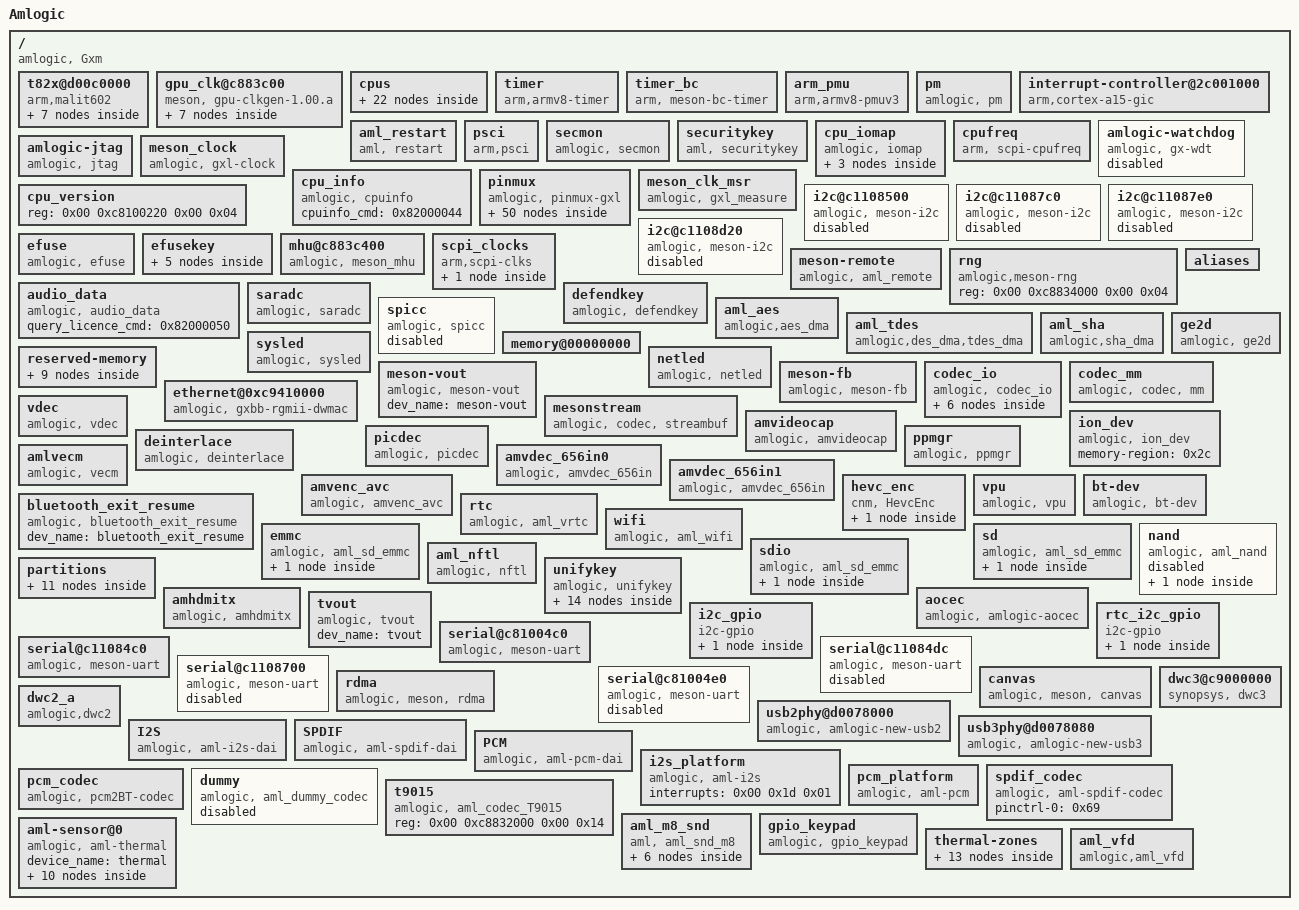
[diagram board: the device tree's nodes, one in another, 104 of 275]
/dts-v1/;

/ {
	model = "Amlogic";
	compatible = "amlogic, Gxm";
	amlogic-dt-id = "gxm_m12s_1g";
	interrupt-parent = <0x01>;
	#address-cells = <0x02>;
	#size-cells = <0x02>;

	t82x@d00c0000 {
		compatible = "arm,malit602", "arm,malit60x", "arm,malit6xx", "arm,mali-midgard";
		#cooling-cells = <0x02>;
		reg = <0x00 0xd00c0000 0x00 0x100000 0x00 0xc1104440 0x00 0x1000 0x00 0xc8100000 0x00 0x1000 0x00 0xc883c000 0x00 0x1000 0x00 0xc1104440 0x00 0x1000>;
		interrupt-parent = <0x01>;
		interrupts = <0x00 0xa0 0x04 0x00 0xa1 0x04 0x00 0xa2 0x04>;
		interrupt-names = "GPU", "MMU", "JOB";
		num_of_pp = <0x03>;
		sc_mpp = <0x01>;
		operating-points = <0xa2c2a 0xf4240 0x7a120 0xf4240 0x61a80 0xf4240 0x45c12 0xf4240 0x3d090 0xf4240 0x1e848 0xf4240>;
		tbl = <0x02 0x03 0x04 0x05 0x05>;
		clocks = <0x06 0x08 0x06 0x09 0x06 0x11 0x06 0x12 0x06 0x1e 0x06 0x15 0x06 0x13 0x06 0x14>;
		clock-names = "fclk_div3", "fclk_div4", "fclk_div5", "fclk_div7", "gp0_pll", "clk_gpu", "clk_gpu_0", "clk_gpu_1";
		linux,phandle = <0x7e>;
		phandle = <0x7e>;

		clk125_cfg {
			clk_freq = <0x7735940>;
			clk_parent = "fclk_div4";
			clkp_freq = <0x1dcd6500>;
			voltage = <0x47e>;
			keep_count = <0x05>;
			threshold = <0x1e 0x78>;
		};

		dvfs250_cfg {
			clk_freq = <0xee6b280>;
			clk_parent = "fclk_div4";
			clkp_freq = <0x1dcd6500>;
			voltage = <0x47e>;
			keep_count = <0x05>;
			threshold = <0x50 0xaa>;
		};

		dvfs285_cfg {
			clk_freq = <0x1107a650>;
			clk_parent = "fclk_div7";
			clkp_freq = <0x1107a650>;
			voltage = <0x47e>;
			keep_count = <0x05>;
			threshold = <0x64 0xbe>;
			linux,phandle = <0x02>;
			phandle = <0x02>;
		};

		dvfs400_cfg {
			clk_freq = <0x17d78400>;
			clk_parent = "fclk_div5";
			clkp_freq = <0x17d78400>;
			voltage = <0x47e>;
			keep_count = <0x05>;
			threshold = <0x98 0xcf>;
			linux,phandle = <0x03>;
			phandle = <0x03>;
		};

		dvfs500_cfg {
			clk_freq = <0x1dcd6500>;
			clk_parent = "fclk_div4";
			clkp_freq = <0x1dcd6500>;
			voltage = <0x47e>;
			keep_count = <0x05>;
			threshold = <0xb4 0xdc>;
			linux,phandle = <0x04>;
			phandle = <0x04>;
		};

		dvfs666_cfg {
			clk_freq = <0x27b25a80>;
			clk_parent = "fclk_div3";
			clkp_freq = <0x27b25a80>;
			voltage = <0x47e>;
			keep_count = <0x05>;
			threshold = <0xd2 0xec>;
			linux,phandle = <0x05>;
			phandle = <0x05>;
		};

		dvfs800_cfg {
			clk_freq = <0x2f34f600>;
			clk_parent = "gp0_pll";
			clkp_freq = <0x2f34f600>;
			voltage = <0x47e>;
			keep_count = <0x05>;
			threshold = <0xe6 0xff>;
		};
	};

	gpu_clk@c883c00 {
		compatible = "meson, gpu-clkgen-1.00.a";
		#clock-cells = <0x00>;
		reg = <0x00 0xc883c000 0x00 0x1000>;
		clocks = <0x06 0x08 0x06 0x09 0x06 0x11 0x06 0x12 0x06 0x1e 0x06 0x15 0x06 0x13 0x06 0x14>;
		clock-names = "fclk_div3", "fclk_div4", "fclk_div5", "fclk_div7", "gp0_pll", "clk_gpu", "clk_gpu_0", "clk_gpu_1";
		clock-output-names = "clk_mali";
		tbl = <0x07 0x08 0x09 0x0a 0x0b 0x0c>;

		clk125_cfg {
			clk_freq = <0x7735940>;
			clk_parent = "fclk_div4";
			clkp_freq = <0x1dcd6500>;
			voltage = <0x47e>;
			keep_count = <0x05>;
			threshold = <0x1e 0x78>;
			linux,phandle = <0x07>;
			phandle = <0x07>;
		};

		clk250_cfg {
			clk_freq = <0xee6b280>;
			clk_parent = "fclk_div4";
			clkp_freq = <0x1dcd6500>;
			voltage = <0x47e>;
			keep_count = <0x05>;
			threshold = <0x50 0xaa>;
			linux,phandle = <0x08>;
			phandle = <0x08>;
		};

		clk285_cfg {
			clk_freq = <0x1107a650>;
			clk_parent = "fclk_div7";
			clkp_freq = <0x1107a650>;
			voltage = <0x47e>;
			keep_count = <0x05>;
			threshold = <0x64 0xbe>;
			linux,phandle = <0x09>;
			phandle = <0x09>;
		};

		clk400_cfg {
			clk_freq = <0x17d78400>;
			clk_parent = "fclk_div5";
			clkp_freq = <0x17d78400>;
			voltage = <0x47e>;
			keep_count = <0x05>;
			threshold = <0x98 0xcf>;
			linux,phandle = <0x0a>;
			phandle = <0x0a>;
		};

		clk500_cfg {
			clk_freq = <0x1dcd6500>;
			clk_parent = "fclk_div4";
			clkp_freq = <0x1dcd6500>;
			voltage = <0x47e>;
			keep_count = <0x05>;
			threshold = <0xb4 0xdc>;
			linux,phandle = <0x0b>;
			phandle = <0x0b>;
		};

		clk666_cfg {
			clk_freq = <0x27bc8410>;
			clk_parent = "fclk_div3";
			clkp_freq = <0x27bc8410>;
			voltage = <0x47e>;
			keep_count = <0x05>;
			threshold = <0xd2 0xec>;
			linux,phandle = <0x0c>;
			phandle = <0x0c>;
		};

		clk720_cfg {
			clk_freq = <0x2aea5400>;
			clk_parent = "gp0_pll";
			clkp_freq = <0x2aea5400>;
			voltage = <0x47e>;
			keep_count = <0x05>;
			threshold = <0xe6 0xff>;
		};
	};

	cpus {
		#address-cells = <0x02>;
		#size-cells = <0x00>;

		cpu-map {

			cluster0 {
				#cooling-cells = <0x02>;
				linux,phandle = <0x7a>;
				phandle = <0x7a>;

				core0 {
					cpu = <0x0d>;
				};

				core1 {
					cpu = <0x0e>;
				};

				core2 {
					cpu = <0x0f>;
				};

				core3 {
					cpu = <0x10>;
				};
			};

			cluster1 {
				#cooling-cells = <0x02>;
				linux,phandle = <0x7b>;
				phandle = <0x7b>;

				core0 {
					cpu = <0x11>;
				};

				core1 {
					cpu = <0x12>;
				};

				core2 {
					cpu = <0x13>;
				};

				core3 {
					cpu = <0x14>;
				};
			};
		};

		cpu@0 {
			device_type = "cpu";
			compatible = "arm,cortex-a53", "arm,armv8";
			reg = <0x00 0x00>;
			enable-method = "psci";
			clocks = <0x15 0x00>;
			clock-names = "cpu-cluster.0";
			cpu-idle-states = <0x16 0x17>;
			linux,phandle = <0x0d>;
			phandle = <0x0d>;
		};

		cpu@1 {
			device_type = "cpu";
			compatible = "arm,cortex-a53", "arm,armv8";
			reg = <0x00 0x01>;
			enable-method = "psci";
			clocks = <0x15 0x00>;
			clock-names = "cpu-cluster.0";
			cpu-idle-states = <0x16 0x17>;
			linux,phandle = <0x0e>;
			phandle = <0x0e>;
		};

		cpu@2 {
			device_type = "cpu";
			compatible = "arm,cortex-a53", "arm,armv8";
			reg = <0x00 0x02>;
			enable-method = "psci";
			clocks = <0x15 0x00>;
			clock-names = "cpu-cluster.0";
			cpu-idle-states = <0x16 0x17>;
			linux,phandle = <0x0f>;
			phandle = <0x0f>;
		};

		cpu@3 {
			device_type = "cpu";
			compatible = "arm,cortex-a53", "arm,armv8";
			reg = <0x00 0x03>;
			enable-method = "psci";
			clocks = <0x15 0x00>;
			clock-names = "cpu-cluster.0";
			cpu-idle-states = <0x16 0x17>;
			linux,phandle = <0x10>;
			phandle = <0x10>;
		};

		cpu@100 {
			device_type = "cpu";
			compatible = "arm,cortex-a53", "arm,armv8";
			reg = <0x00 0x100>;
			enable-method = "psci";
			clocks = <0x15 0x01>;
			clock-names = "cpu-cluster.1";
			cpu-idle-states = <0x16 0x17>;
			linux,phandle = <0x11>;
			phandle = <0x11>;
		};

		cpu@101 {
			device_type = "cpu";
			compatible = "arm,cortex-a53", "arm,armv8";
			reg = <0x00 0x101>;
			enable-method = "psci";
			clocks = <0x15 0x01>;
			clock-names = "cpu-cluster.1";
			cpu-idle-states = <0x16 0x17>;
			linux,phandle = <0x12>;
			phandle = <0x12>;
		};

		cpu@102 {
			device_type = "cpu";
			compatible = "arm,cortex-a53", "arm,armv8";
			reg = <0x00 0x102>;
			enable-method = "psci";
			clocks = <0x15 0x01>;
			clock-names = "cpu-cluster.1";
			cpu-idle-states = <0x16 0x17>;
			linux,phandle = <0x13>;
			phandle = <0x13>;
		};

		cpu@103 {
			device_type = "cpu";
			compatible = "arm,cortex-a53", "arm,armv8";
			reg = <0x00 0x103>;
			enable-method = "psci";
			clocks = <0x15 0x01>;
			clock-names = "cpu-cluster.1";
			cpu-idle-states = <0x16 0x17>;
			linux,phandle = <0x14>;
			phandle = <0x14>;
		};

		idle-states {
			entry-method = "arm,psci";

			cpu-sleep-0 {
				compatible = "arm, idle-state";
				arm,psci-suspend-param = <0x10000>;
				local-timer-stop;
				entry-latency-us = <0x1388>;
				exit-latency-us = <0x1f40>;
				min-residency-us = <0x4e20>;
				linux,phandle = <0x16>;
				phandle = <0x16>;
			};

			cluster-sleep-0 {
				compatible = "arm, idle-state";
				arm,psci-suspend-param = <0x1010000>;
				local-timer-stop;
				entry-latency-us = <0x1388>;
				exit-latency-us = <0x1f40>;
				min-residency-us = <0x61a8>;
				linux,phandle = <0x17>;
				phandle = <0x17>;
			};
		};
	};

	timer {
		compatible = "arm,armv8-timer";
		interrupts = <0x01 0x0d 0xff01 0x01 0x0e 0xff01 0x01 0x0b 0xff01 0x01 0x0a 0xff01>;
	};

	timer_bc {
		compatible = "arm, meson-bc-timer";
		reg = <0x00 0xc1109990 0x00 0x04 0x00 0xc1109994 0x00 0x04>;
		timer_name = "Meson TimerF";
		clockevent-rating = <0x12c>;
		clockevent-shift = <0x14>;
		clockevent-features = <0x23>;
		interrupts = <0x00 0x3c 0x01>;
		bit_enable = <0x10>;
		bit_mode = <0x0c>;
		bit_resolution = <0x00>;
	};

	arm_pmu {
		compatible = "arm,armv8-pmuv3";
		interrupts = <0x00 0x89 0x04 0x00 0x8a 0x04 0x00 0x99 0x04 0x00 0x9a 0x04>;
	};

	pm {
		compatible = "amlogic, pm";
		device_name = "aml_pm";
		gxbaby-suspend;
		reg = <0x00 0xc81000a8 0x00 0x04 0x00 0xc810023c 0x00 0x04>;
	};

	interrupt-controller@2c001000 {
		compatible = "arm,cortex-a15-gic", "arm,cortex-a9-gic";
		#interrupt-cells = <0x03>;
		#address-cells = <0x00>;
		interrupt-controller;
		reg = <0x00 0xc4301000 0x00 0x1000 0x00 0xc4302000 0x00 0x100>;
		interrupts = <0x01 0x09 0xf04>;
		linux,phandle = <0x01>;
		phandle = <0x01>;
	};

	aml_restart {
		compatible = "aml, restart";
		sys_reset = <0x84000009>;
		sys_poweroff = <0x84000008>;
	};

	psci {
		compatible = "arm,psci";
		method = "smc";
		cpu_suspend = <0xc4000001>;
		cpu_off = <0x84000002>;
		cpu_on = <0xc4000003>;
		migrate = <0xc4000005>;
	};

	secmon {
		compatible = "amlogic, secmon";
		memory-region = <0x18>;
		in_base_func = <0x82000020>;
		out_base_func = <0x82000021>;
	};

	securitykey {
		compatible = "aml, securitykey";
		storage_query = <0x82000060>;
		storage_read = <0x82000061>;
		storage_write = <0x82000062>;
		storage_tell = <0x82000063>;
		storage_verify = <0x82000064>;
		storage_status = <0x82000065>;
		storage_list = <0x82000067>;
		storage_remove = <0x82000068>;
		storage_in_func = <0x82000023>;
		storage_out_func = <0x82000024>;
		storage_block_func = <0x82000025>;
		storage_size_func = <0x82000027>;
	};

	cpu_iomap {
		compatible = "amlogic, iomap";
		#address-cells = <0x02>;
		#size-cells = <0x02>;
		ranges;

		io_cbus_base {
			reg = <0x00 0xc1100000 0x00 0x100000>;
		};

		io_apb_base {
			reg = <0x00 0xd0000000 0x00 0x200000>;
		};

		io_aobus_base {
			reg = <0x00 0xc8100000 0x00 0x100000>;
		};
	};

	cpufreq {
		compatible = "arm, scpi-cpufreq";
	};

	amlogic-watchdog {
		compatible = "amlogic, gx-wdt";
		status = "disable";
		default_timeout = <0x0a>;
		reset_watchdog_method = <0x01>;
		reset_watchdog_time = <0x02>;
		shutdown_timeout = <0x0a>;
		firmware_timeout = <0x06>;
		suspend_timeout = <0x06>;
		reg = <0x00 0xc11098d0 0x00 0x10>;
		clocks = <0x06 0x02>;
	};

	amlogic-jtag {
		compatible = "amlogic, jtag";
		status = "okay";
		pinctrl-names = "jtag_apao_pins", "jtag_apee_pins";
		pinctrl-0 = <0x19>;
		pinctrl-1 = <0x1a>;
	};

	meson_clock {
		compatible = "amlogic, gxl-clock";
		reg = <0x00 0xc883c000 0x00 0x1000 0x00 0xc8100000 0x00 0x1000>;
		#clock-cells = <0x01>;
		#reset-cells = <0x01>;
		sys_max = <0x5b8d8000>;
		linux,phandle = <0x06>;
		phandle = <0x06>;
	};

	cpu_info {
		compatible = "amlogic, cpuinfo";
		cpuinfo_cmd = <0x82000044>;
	};

	pinmux {
		compatible = "amlogic, pinmux-gxl";
		dev_name = "pinmux";
		#pinmux-cells = <0x02>;
		#address-cells = <0x02>;
		#size-cells = <0x02>;
		reg = <0x00 0xc1109880 0x00 0x10>;
		ranges;

		banks@c11080b0 {
			reg = <0x00 0xc88344b0 0x00 0x28 0x00 0xc88344e8 0x00 0x14 0x00 0xc8834520 0x00 0x14 0x00 0xc8834430 0x00 0x40>;
			reg-names = "mux", "pull", "pull-enable", "gpio";
			gpio-controller;
			#gpio-cells = <0x02>;
			linux,phandle = <0x28>;
			phandle = <0x28>;
		};

		ao-bank@c1108030 {
			reg = <0x00 0xc8100014 0x00 0x08 0x00 0xc810002c 0x00 0x04 0x00 0xc8100024 0x00 0x08>;
			reg-names = "mux", "pull", "gpio";
			gpio-controller;
			#gpio-cells = <0x02>;
			linux,phandle = <0x27>;
			phandle = <0x27>;
		};

		external_eth_pins {
			amlogic,setmask = <0x04 0xfffc00>;
			amlogic,clrmask = <0x04 0x3fc 0x03 0xffcff800>;
			amlogic,pins = "GPIOZ_0", "GPIOZ_1", "GPIOZ_2", "GPIOZ_3", "GPIOZ_4", "GPIOZ_5", "GPIOZ_6", "GPIOZ_7", "GPIOZ_8", "GPIOZ_9", "GPIOZ_10", "GPIOZ_11", "GPIOZ_12", "GPIOZ_13";
			linux,phandle = <0x2b>;
			phandle = <0x2b>;
		};

		internal_eth_pins {
			amlogic,setmask = <0x04 0x3000000>;
			amlogic,clrmask = <0x03 0x300000>;
			amlogic,pins = "GPIOZ_14", "GPIOZ_15";
		};

		jtag_apao_pin {
			amlogic,clrmask = <0x06 0x7fe0000>;
			amlogic,pins = "GPIOH_6", "GPIOH_7", "GPIOH_8", "GPIOH_9";
			linux,phandle = <0x19>;
			phandle = <0x19>;
		};

		jtag_apee_pin {
			amlogic,clrmask = <0x06 0x3c>;
			amlogic,pins = "CARD_0", "CARD_1", "CARD_2", "CARD_3";
			linux,phandle = <0x1a>;
			phandle = <0x1a>;
		};

		remote_pin {
			amlogic,setmask = <0x10 0x01>;
			amlogic,pins = "GPIOAO_7";
			linux,phandle = <0x26>;
			phandle = <0x26>;
		};

		ao_uart {
			amlogic,setmask = <0x10 0x1800>;
			amlogic,pins = "GPIOAO_0", "GPIOAO_1";
		};

		ao_b_uart {
			amlogic,setmask = <0x10 0x1800000>;
			amlogic,pins = "GPIOAO_4", "GPIOAO_5";
			linux,phandle = <0x65>;
			phandle = <0x65>;
		};

		a_uart {
			amlogic,setmask = <0x05 0xf0000>;
			amlogic,clrmask = <0x05 0x3c0>;
			amlogic,pins = "GPIOX_12", "GPIOX_13", "GPIOX_14", "GPIOX_15";
			linux,phandle = <0x62>;
			phandle = <0x62>;
		};

		b_uart {
			amlogic,setmask = <0x02 0x18000>;
			amlogic,pins = "GPIODV_24", "GPIODV_25";
			linux,phandle = <0x63>;
			phandle = <0x63>;
		};

		c_uart {
			amlogic,setmask = <0x05 0x3000>;
			amlogic,pins = "GPIOX_8", "GPIOX_9";
			linux,phandle = <0x64>;
			phandle = <0x64>;
		};

		wifi_32k_pins {
			amlogic,setmask = <0x05 0x8000>;
			amlogic,pins = "GPIOX_16";
			linux,phandle = <0x30>;
			phandle = <0x30>;
		};

		sd_clk_cmd_pins {
			amlogic,setmask = <0x06 0x0c 0x10 0x1800>;
			amlogic,pins = "CARD_2", "CARD_3";
			amlogic,enable-output = <0x01>;
			amlogic,pullup = <0x01>;
			amlogic,pullupen = <0x01>;
			linux,phandle = <0x35>;
			phandle = <0x35>;
		};

		sd_all_pins {
			amlogic,setmask = <0x06 0x3f 0x10 0x1800>;
			amlogic,clrmask = <0x06 0xfc0>;
			amlogic,pins = "CARD_0", "CARD_1", "CARD_2", "CARD_3", "CARD_4", "CARD_5";
			amlogic,enable-output = <0x01>;
			amlogic,pullup = <0x01>;
			amlogic,pullupen = <0x01>;
			linux,phandle = <0x36>;
			phandle = <0x36>;
		};

		sd_1bit_pins {
			amlogic,setmask = <0x06 0x1c 0x10 0x1800>;
			amlogic,clrmask = <0x06 0xcc3>;
			amlogic,pins = "CARD_1", "CARD_2", "CARD_3";
			amlogic,enable-output = <0x01>;
			amlogic,pullup = <0x01>;
			amlogic,pullupen = <0x01>;
			linux,phandle = <0x37>;
			phandle = <0x37>;
		};

		sd_clk_cmd_uart_pins {
			amlogic,setmask = <0x06 0x30c>;
			amlogic,clrmask = <0x06 0xcc3 0x10 0x1800>;
			amlogic,pins = "CARD_2", "CARD_3";
			amlogic,enable-output = <0x01>;
			amlogic,pullup = <0x01>;
			amlogic,pullupen = <0x01>;
			linux,phandle = <0x38>;
			phandle = <0x38>;
		};

		sd_1bit_uart_pins {
			amlogic,setmask = <0x06 0x31c>;
			amlogic,clrmask = <0x06 0xcc3 0x10 0x1800>;
			amlogic,pins = "CARD_1", "CARD_2", "CARD_3";
			amlogic,enable-output = <0x01>;
			amlogic,pullup = <0x01>;
			amlogic,pullupen = <0x01>;
			linux,phandle = <0x39>;
			phandle = <0x39>;
		};

		sd_to_ao_uart_pins {
			amlogic,setmask = <0x10 0x1800>;
			amlogic,clrmask = <0x06 0x300>;
			amlogic,pins = "GPIOAO_0", "GPIOAO_1";
			amlogic,enable-output = <0x01>;
			amlogic,pullup = <0x01>;
			amlogic,pullupen = <0x01>;
			linux,phandle = <0x3a>;
			phandle = <0x3a>;
		};

		ao_to_sd_uart_pins {
			amlogic,setmask = <0x06 0x300>;
			amlogic,clrmask = <0x10 0x1800 0x06 0xcc3>;
			amlogic,pins = "CARD_4", "CARD_5";
			amlogic,enable-output = <0x01>;
			amlogic,pullup = <0x01>;
			amlogic,pullupen = <0x01>;
			linux,phandle = <0x3b>;
			phandle = <0x3b>;
		};

		ao_to_sd_jtag_pins {
			amlogic,setmask = <0x06 0x300>;
			amlogic,clrmask = <0x06 0xcff 0x10 0x1800>;
			amlogic,pins = "CARD_4", "CARD_5";
			amlogic,enable-output = <0x01>;
			amlogic,pullup = <0x01>;
			amlogic,pullupen = <0x01>;
			linux,phandle = <0x3c>;
			phandle = <0x3c>;
		};

		sd_to_ao_jtag_pins {
			amlogic,setmask = <0x10 0x1800>;
			amlogic,clrmask = <0x06 0xfc0>;
			amlogic,pins = "GPIOAO_0", "GPIOAO_1";
			amlogic,enable-output = <0x01>;
			amlogic,pullup = <0x01>;
			amlogic,pullupen = <0x01>;
			linux,phandle = <0x3d>;
			phandle = <0x3d>;
		};

		emmc_clk_cmd_pins {
			amlogic,setmask = <0x07 0x60000000>;
			amlogic,clrmask = <0x07 0xe0>;
			amlogic,pins = "BOOT_8", "BOOT_10";
			amlogic,enable-output = <0x01>;
			amlogic,pullup = <0x01>;
			amlogic,pullupen = <0x01>;
			linux,phandle = <0x31>;
			phandle = <0x31>;
		};

		emmc_conf_pull_up {
			amlogic,pins = "BOOT_0", "BOOT_1", "BOOT_2", "BOOT_3", "BOOT_4", "BOOT_5", "BOOT_6", "BOOT_7", "BOOT_8", "BOOT_10";
			amlogic,pullup = <0x01>;
			amlogic,pullupen = <0x01>;
			linux,phandle = <0x32>;
			phandle = <0x32>;
		};

		emmc_conf_pull_done {
			amlogic,pins = "BOOT_15";
			amlogic,pullup = <0x00>;
			amlogic,pullupen = <0x01>;
			linux,phandle = <0x33>;
			phandle = <0x33>;
		};

		emmc_all_pins {
			amlogic,setmask = <0x07 0xf0000000>;
			amlogic,clrmask = <0x07 0xe0>;
			amlogic,pins = "BOOT_0", "BOOT_1", "BOOT_2", "BOOT_3", "BOOT_4", "BOOT_5", "BOOT_6", "BOOT_7", "BOOT_8", "BOOT_10", "BOOT_15";
			amlogic,enable-output = <0x01>;
			linux,phandle = <0x34>;
			phandle = <0x34>;
		};

		sdio_clk_cmd_pins {
			amlogic,setmask = <0x05 0xc000000>;
			amlogic,pins = "GPIOX_4", "GPIOX_5";
			amlogic,enable-output = <0x01>;
			amlogic,pullup = <0x01>;
			amlogic,pullupen = <0x01>;
			linux,phandle = <0x3e>;
			phandle = <0x3e>;
		};

		sdio_all_pins {
			amlogic,setmask = <0x05 0xfc000000>;
			amlogic,pins = "GPIOX_0", "GPIOX_1", "GPIOX_2", "GPIOX_3", "GPIOX_4", "GPIOX_5";
			amlogic,enable-output = <0x01>;
			amlogic,pullup = <0x01>;
			amlogic,pullupen = <0x01>;
			linux,phandle = <0x3f>;
			phandle = <0x3f>;
		};

		conf_nand_pulldown {
			amlogic,pins = "BOOT_0", "BOOT_1", "BOOT_2", "BOOT_3", "BOOT_4", "BOOT_5", "BOOT_6", "BOOT_7", "BOOT_15";
			amlogic,pullup = <0x00>;
			amlogic,pullupen = <0x01>;
			linux,phandle = <0x40>;
			phandle = <0x40>;
		};

		conf_nand_pullup {
			amlogic,pins = "BOOT_8", "BOOT_10";
			amlogic,pullup = <0x01>;
			amlogic,pullupen = <0x01>;
			linux,phandle = <0x41>;
			phandle = <0x41>;
		};

		all_nand_pins {
			amlogic,setmask = <0x07 0x800000ff>;
			amlogic,clrmask = <0x07 0x70ffbc00>;
			amlogic,pins = "BOOT_0", "BOOT_1", "BOOT_2", "BOOT_3", "BOOT_4", "BOOT_5", "BOOT_6", "BOOT_7", "BOOT_8", "BOOT_9", "BOOT_10", "BOOT_11", "BOOT_12", "BOOT_13", "BOOT_14", "BOOT_15";
			amlogic,enable-output = <0x01>;
			linux,phandle = <0x42>;
			phandle = <0x42>;
		};

		nand_cs {
			amlogic,setmask = <0x07 0xc0>;
			amlogic,clrmask = <0x07 0x40040000>;
			amlogic,pins = "BOOT_8", "BOOT_9";
			linux,phandle = <0x43>;
			phandle = <0x43>;
		};

		hdmitx_hpd {
			amlogic,setmask = <0x06 0x80000000>;
			amlogic,pins = "GPIOH_0";
			linux,phandle = <0x5e>;
			phandle = <0x5e>;
		};

		hdmitx_ddc {
			amlogic,setmask = <0x06 0x30000000>;
			amlogic,pins = "GPIOH_1", "GPIOH_2";
			linux,phandle = <0x5f>;
			phandle = <0x5f>;
		};

		rtc_i2c_hym8563_pin {
			amlogic,setmask = <0x01 0x30000>;
			amlogic,clrmask = <0x03 0x20 0x01 0x2000000>;
			amlogic,pins = "GPIODV_18", "GPIODV_19";
			linux,phandle = <0x61>;
			phandle = <0x61>;
		};

		hdmitx_aocec {
			amlogic,setmask = <0x10 0x8000>;
			amlogic,clrmask = <0x10 0x24000 0x11 0x01>;
			amlogic,pins = "GPIOAO_8";
			linux,phandle = <0x60>;
			phandle = <0x60>;
		};

		hdmitx_eecec {
			amlogic,setmask = <0x10 0x4000>;
			amlogic,clrmask = <0x10 0x28000 0x11 0x01>;
			amlogic,pins = "GPIOAO_8";
		};

		a_i2c {
			amlogic,setmask = <0x01 0xc000>;
			amlogic,clrmask = <0x03 0x18 0x02 0x18000 0x02 0xc0 0x01 0x600000>;
			amlogic,pins = "GPIODV_24", "GPIODV_25";
			linux,phandle = <0x1b>;
			phandle = <0x1b>;
		};

		b_i2c {
			amlogic,setmask = <0x01 0x3000>;
			amlogic,clrmask = <0x02 0x6000 0x01 0x1c0000>;
			amlogic,pins = "GPIODV_26", "GPIODV_27";
			linux,phandle = <0x1c>;
			phandle = <0x1c>;
		};

		c_i2c {
			amlogic,setmask = <0x01 0xc00>;
			amlogic,clrmask = <0x02 0x1800 0x01 0x200 0x02 0x20>;
			amlogic,pins = "GPIODV_28", "GPIODV_29";
			linux,phandle = <0x1d>;
			phandle = <0x1d>;
		};

		d_i2c {
			amlogic,setmask = <0x05 0x30>;
			amlogic,clrmask = <0x05 0x300c03>;
			amlogic,pins = "GPIOX_10", "GPIOX_11";
			linux,phandle = <0x1e>;
			phandle = <0x1e>;
		};

		spicc_pins_z11z12z13 {
			amlogic,setmask = <0x04 0x1c>;
			amlogic,clrmask = <0x03 0x800 0x04 0x1c00>;
			amlogic,pins = "GPIOZ_11", "GPIOZ_12", "GPIOZ_13";
		};

		spicc_pulldown_z11z12z13 {
			amlogic,pins = "GPIOZ_11", "GPIOZ_12", "GPIOZ_13";
			amlogic,pullup = <0x00>;
			amlogic,pullupen = <0x01>;
		};

		spicc_pullup_z11z12z13 {
			amlogic,pins = "GPIOZ_11", "GPIOZ_12", "GPIOZ_13";
			amlogic,pullup = <0x01>;
			amlogic,pullupen = <0x01>;
		};

		spicc_pins_x8x9x11 {
			amlogic,setmask = <0x05 0x0d>;
			amlogic,clrmask = <0x05 0xd03430 0x06 0x0d>;
			amlogic,pins = "GPIOX_8", "GPIOX_9", "GPIOX_11";
		};

		spicc_pulldown_x8x9x11 {
			amlogic,pins = "GPIOX_8", "GPIOX_9", "GPIOX_11";
			amlogic,pullup = <0x00>;
			amlogic,pullupen = <0x01>;
		};

		spicc_pullup_x8x9x11 {
			amlogic,pins = "GPIOX_8", "GPIOX_9", "GPIOX_11";
			amlogic,pullup = <0x01>;
			amlogic,pullupen = <0x01>;
		};

		audio_pin {
			amlogic,setmask = <0x06 0x7800000>;
			amlogic,clrmask = <0x06 0x7e0000>;
			amlogic,pins = "GPIOH_6", "GPIOH_7", "GPIOH_8", "GPIOH_9";
		};

		audio_pin1 {
			amlogic,setmask = <0x06 0x10000000>;
			amlogic,clrmask = <0x06 0x8000000>;
			amlogic,pins = "GPIOH_4";
			linux,phandle = <0x69>;
			phandle = <0x69>;
		};

		audio_btpcm_pins {
			amlogic,setmask = <0x05 0xf00000>;
			amlogic,clrmask = <0x05 0x3c33>;
			amlogic,pins = "GPIOX_8", "GPIOX_9", "GPIOX_10", "GPIOX_11";
			linux,phandle = <0x68>;
			phandle = <0x68>;
		};
	};

	cpu_version {
		reg = <0x00 0xc8100220 0x00 0x04>;
	};

	meson_clk_msr {
		compatible = "amlogic, gxl_measure";
		reg = <0x00 0xc110875c 0x00 0x04 0x00 0xc1108764 0x00 0x04>;
	};

	i2c@c1108500 {
		compatible = "amlogic, meson-i2c";
		dev_name = "i2c-A";
		status = "disabled";
		reg = <0x00 0xc1108500 0x00 0x20>;
		device_id = <0x01>;
		pinctrl-names = "default";
		pinctrl-0 = <0x1b>;
		#address-cells = <0x01>;
		#size-cells = <0x00>;
		use_pio = <0x00>;
		master_i2c_speed = <0x493e0>;
		clocks = <0x06 0x0a>;
		clock-names = "clk_i2c";
		resets = <0x06 0x09>;
	};

	i2c@c11087c0 {
		compatible = "amlogic, meson-i2c";
		dev_name = "i2c-B";
		status = "disabled";
		reg = <0x00 0xc11087c0 0x00 0x20>;
		device_id = <0x02>;
		pinctrl-names = "default";
		pinctrl-0 = <0x1c>;
		#address-cells = <0x01>;
		#size-cells = <0x00>;
		use_pio = <0x00>;
		master_i2c_speed = <0x493e0>;
		clocks = <0x06 0x0a>;
		clock-names = "clk_i2c";
		resets = <0x06 0x09>;
	};

	i2c@c11087e0 {
		compatible = "amlogic, meson-i2c";
		dev_name = "i2c-C";
		status = "disabled";
		reg = <0x00 0xc11087e0 0x00 0x20>;
		device_id = <0x03>;
		pinctrl-names = "default";
		pinctrl-0 = <0x1d>;
		#address-cells = <0x01>;
		#size-cells = <0x00>;
		use_pio = <0x00>;
		master_i2c_speed = <0x493e0>;
		clocks = <0x06 0x0a>;
		clock-names = "clk_i2c";
		resets = <0x06 0x09>;
	};

	i2c@c1108d20 {
		compatible = "amlogic, meson-i2c";
		dev_name = "i2c-D";
		status = "disabled";
		reg = <0x00 0xc1108d20 0x00 0x20>;
		device_id = <0x04>;
		pinctrl-names = "default";
		pinctrl-0 = <0x1e>;
		#address-cells = <0x01>;
		#size-cells = <0x00>;
		use_pio = <0x00>;
		master_i2c_speed = <0x493e0>;
		clocks = <0x06 0x0a>;
		clock-names = "clk_i2c";
		resets = <0x06 0x09>;
	};

	efuse {
		compatible = "amlogic, efuse";
		read_cmd = <0x82000030>;
		write_cmd = <0x82000031>;
		get_max_cmd = <0x82000033>;
		key = <0x1f>;
		resets = <0x06 0x3e>;
		reset-names = "efuse_clk";
		status = "ok";
	};

	efusekey {
		keynum = <0x05>;
		key0 = <0x20>;
		key1 = <0x21>;
		key2 = <0x22>;
		key3 = <0x23>;
		key4 = <0x24>;
		linux,phandle = <0x1f>;
		phandle = <0x1f>;

		key0 {
			keyname = "mac";
			offset = <0x00>;
			size = <0x06>;
			linux,phandle = <0x20>;
			phandle = <0x20>;
		};

		key1 {
			keyname = "mac_bt";
			offset = <0x06>;
			size = <0x06>;
			linux,phandle = <0x21>;
			phandle = <0x21>;
		};

		key2 {
			keyname = "mac_wifi";
			offset = <0x0c>;
			size = <0x06>;
			linux,phandle = <0x22>;
			phandle = <0x22>;
		};

		key3 {
			keyname = "usid";
			offset = <0x12>;
			size = <0x10>;
			linux,phandle = <0x23>;
			phandle = <0x23>;
		};

		key4 {
			keyname = "randomid";
			offset = <0x22>;
			size = <0x08>;
			linux,phandle = <0x24>;
			phandle = <0x24>;
		};
	};

	mhu@c883c400 {
		compatible = "amlogic, meson_mhu";
		reg = <0x00 0xc883c400 0x00 0x4c 0x00 0xc8013000 0x00 0x800>;
		interrupts = <0x00 0xd1 0x08 0x00 0xd2 0x08>;
		#mbox-cells = <0x01>;
		mbox-names = "cpu_to_scp_low", "cpu_to_scp_high";
		mboxes = <0x25 0x00 0x25 0x01>;
		linux,phandle = <0x25>;
		phandle = <0x25>;
	};

	scpi_clocks {
		compatible = "arm,scpi-clks";

		scpi_clocks@0 {
			compatible = "arm,scpi-clk-indexed";
			#clock-cells = <0x01>;
			clock-indices = <0x00 0x01>;
			clock-output-names = "vbig", "vlittle";
			linux,phandle = <0x15>;
			phandle = <0x15>;
		};
	};

	meson-remote {
		compatible = "amlogic, aml_remote";
		dev_name = "meson-remote";
		status = "okay";
		remote_ao_offset = <0x580>;
		interrupts = <0x00 0xc4 0x01>;
		pinctrl-names = "default";
		pinctrl-0 = <0x26>;
	};

	rng {
		compatible = "amlogic,meson-rng";
		reg = <0x00 0xc8834000 0x00 0x04>;
	};

	audio_data {
		compatible = "amlogic, audio_data";
		query_licence_cmd = <0x82000050>;
		status = "okay";
	};

	saradc {
		compatible = "amlogic, saradc";
		status = "okay";
		interrupts = <0x00 0x09 0x01>;
		interrupt-names = "saradc_int";
		clocks = <0x06 0x02>;
		clock-names = "saradc_clk";
		resets = <0x06 0x56>;
		reg = <0x00 0xc1108680 0x00 0x30 0x00 0xc883c3d8 0x00 0x08>;
	};

	defendkey {
		compatible = "amlogic, defendkey";
		reg = <0x00 0xc8834500 0x00 0x04>;
		mem_size = <0x00 0x100000>;
		status = "okay";
	};

	spicc {
		compatible = "amlogic, spicc";
		status = "disabled";
		reg = <0x00 0xc1108d80 0x00 0x28>;
		resets = <0x06 0x08>;
		clocks = <0x06 0x0a>;
		clock-names = "spicc_clk";
		interrupts = <0x00 0x51 0x01>;
		device_id = <0x00>;
	};

	aml_aes {
		compatible = "amlogic,aes_dma";
		dev_name = "aml_aes_dma";
		interrupts = <0x00 0xbc 0x01 0x00 0xbd 0x01>;
		reg = <0x00 0xc883e000 0x00 0x28>;
	};

	aml_tdes {
		compatible = "amlogic,des_dma,tdes_dma";
		dev_name = "aml_tdes_dma";
		interrupts = <0x00 0xbc 0x01 0x00 0xbd 0x01>;
		reg = <0x00 0xc883e000 0x00 0x28>;
	};

	aml_sha {
		compatible = "amlogic,sha_dma";
		dev_name = "aml_sha_dma";
		interrupts = <0x00 0xbc 0x01 0x00 0xbd 0x01>;
		reg = <0x00 0xc883e000 0x00 0x28>;
	};

	aliases {
		serial0 = "/serial@c81004c0";
		serial1 = "/serial@c11084c0";
		serial2 = "/serial@c11084dc";
		serial3 = "/serial@c1108700";
		serial4 = "/serial@c81004e0";
	};

	memory@00000000 {
		device_type = "memory";
		linux,usable-memory = <0x00 0x100000 0x00 0x3f000000>;
	};

	reserved-memory {
		#address-cells = <0x02>;
		#size-cells = <0x02>;
		ranges;

		linux,secmon {
			compatible = "amlogic, aml_secmon_memory";
			reg = <0x00 0x10000000 0x00 0x200000>;
			no-map;
			linux,phandle = <0x18>;
			phandle = <0x18>;
		};

		linux,secos {
			status = "disable";
			compatible = "amlogic, aml_secos_memory";
			reg = <0x00 0x5300000 0x00 0x2000000>;
			no-map;
		};

		aml_pstore {
			compatible = "amlogic, pstore";
			reg = <0x00 0x7300000 0x00 0x100000>;
			no-map;
		};

		linux,di {
			compatible = "amlogic, di-mem";
			size = <0x00 0x1e00000>;
			linux,phandle = <0x2f>;
			phandle = <0x2f>;
		};

		linux,ion-dev {
			compatible = "amlogic, idev-mem";
			size = <0x00 0x4000000>;
			linux,phandle = <0x2c>;
			phandle = <0x2c>;
		};

		linux,ppmgr {
			compatible = "shared-dma-pool";
			size = <0x00 0x00>;
			linux,phandle = <0x2e>;
			phandle = <0x2e>;
		};

		linux,codec_mm_cma {
			compatible = "shared-dma-pool";
			reusable;
			size = <0x00 0xc000000>;
			alignment = <0x00 0x400000>;
			linux,contiguous-region;
			linux,phandle = <0x29>;
			phandle = <0x29>;
		};

		linux,picdec {
			compatible = "shared-dma-pool";
			reusable;
			size = <0x00 0x00>;
			alignment = <0x00 0x00>;
			linux,contiguous-region;
			linux,phandle = <0x2d>;
			phandle = <0x2d>;
		};

		linux,codec_mm_reserved {
			compatible = "amlogic, codec-mm-reserved";
			size = <0x00 0x4100000>;
			alignment = <0x00 0x100000>;
			linux,phandle = <0x2a>;
			phandle = <0x2a>;
		};
	};

	sysled {
		compatible = "amlogic, sysled";
		dev_name = "sysled";
		status = "okay";
		led_gpio = <0x27 0x09 0x00>;
		led_active_low = <0x01>;
	};

	netled {
		compatible = "amlogic, netled";
		dev_name = "netled";
		status = "okay";
		led_gpio = <0x28 0x4a 0x00>;
		led_active_low = <0x00>;
	};

	meson-vout {
		compatible = "amlogic, meson-vout";
		dev_name = "meson-vout";
		status = "okay";
	};

	meson-fb {
		compatible = "amlogic, meson-fb";
		dev_name = "meson-fb";
		status = "okay";
		interrupts = <0x00 0x03 0x01 0x00 0x59 0x01>;
		interrupt-names = "viu-vsync", "rdma";
		mem_size = <0x1851000 0x100000>;
		display_mode_default = "1080p60hz";
		scale_mode = <0x01>;
		display_size_default = <0x780 0x438 0x780 0xca8 0x20>;
		logo_addr = "0x3d851000";
	};

	ge2d {
		compatible = "amlogic, ge2d";
		dev_name = "ge2d";
		status = "okay";
		interrupts = <0x00 0x96 0x01>;
		interrupt-names = "ge2d";
		clocks = <0x06 0x17 0x06 0x19>;
		clock-names = "clk_vapb_0", "clk_ge2d";
		resets = <0x06 0x34>;
		reset-names = "ge2d";
	};

	codec_io {
		compatible = "amlogic, codec_io";
		#address-cells = <0x02>;
		#size-cells = <0x02>;
		ranges;

		io_cbus_base {
			reg = <0x00 0xc1100000 0x00 0x100000>;
		};

		io_dos_base {
			reg = <0x00 0xc8820000 0x00 0x10000>;
		};

		io_hiubus_base {
			reg = <0x00 0xc883c000 0x00 0x2000>;
		};

		io_aobus_base {
			reg = <0x00 0xc8100000 0x00 0x100000>;
		};

		io_vcbus_base {
			reg = <0x00 0xd0100000 0x00 0x40000>;
		};

		io_dmc_base {
			reg = <0x00 0xc8838000 0x00 0x400>;
		};
	};

	codec_mm {
		compatible = "amlogic, codec, mm";
		memory-region = <0x29 0x2a>;
		dev_name = "codec_mm";
		status = "okay";
	};

	ethernet@0xc9410000 {
		compatible = "amlogic, gxbb-rgmii-dwmac";
		reg = <0x00 0xc9410000 0x00 0x10000 0x00 0xc8834540 0x00 0x08 0x00 0xc8834558 0x00 0x0c>;
		interrupts = <0x00 0x08 0x01>;
		phy-mode = "rgmii";
		pinctrl-names = "external_eth_pins";
		pinctrl-0 = <0x2b>;
		rst_pin-gpios = <0x28 0x0e 0x00>;
		GPIOZ4_pin-gpios = <0x28 0x04 0x00>;
		GPIOZ5_pin-gpios = <0x28 0x05 0x00>;
		mc_val = <0x1621>;
		cali_val = <0x20000>;
		resets = <0x06 0x23>;
		reset-names = "ethpower";
		interrupt-names = "macirq";
		clocks = <0x06 0x0a>;
		clock-names = "ethclk81";
		internal_phy = <0x00>;
	};

	mesonstream {
		compatible = "amlogic, codec, streambuf";
		dev_name = "mesonstream";
		status = "okay";
		resets = <0x06 0x39 0x06 0x59 0x06 0x24 0x06 0x01>;
		reset-names = "parser_top", "vpu_intr", "demux", "vdec";
	};

	amvideocap {
		compatible = "amlogic, amvideocap";
		dev_name = "amvideocap.0";
		status = "okay";
		max_size = <0x08>;
	};

	ion_dev {
		compatible = "amlogic, ion_dev";
		memory-region = <0x2c>;
	};

	vdec {
		compatible = "amlogic, vdec";
		dev_name = "vdec.0";
		status = "okay";
		interrupts = <0x00 0x03 0x01 0x00 0x17 0x01 0x00 0x20 0x01 0x00 0x2b 0x01 0x00 0x2c 0x01 0x00 0x2d 0x01>;
		interrupt-names = "vsync", "demux", "parser", "mailbox_0", "mailbox_1", "mailbox_2";
	};

	picdec {
		compatible = "amlogic, picdec";
		memory-region = <0x2d>;
		dev_name = "picdec";
		status = "okay";
	};

	ppmgr {
		compatible = "amlogic, ppmgr";
		memory-region = <0x2e>;
		dev_name = "ppmgr";
		status = "okay";
	};

	deinterlace {
		compatible = "amlogic, deinterlace";
		status = "okay";
		memory-region = <0x2f>;
		interrupts = <0x00 0x2e 0x01 0x00 0x06 0x01>;
		interrupt-names = "de_irq", "timerc";
		buffer-size = <0x2fd000>;
		hw-version = <0x02>;
	};

	amvdec_656in0 {
		compatible = "amlogic, amvdec_656in";
		dev_name = "amvdec_656in0";
		status = "ok";
		reg = <0x00 0xd0048000 0x00 0x7c>;
		clocks = <0x06 0x07 0x06 0x26>;
		clock-names = "fclk_div2", "cts_bt656_clk0";
		bt656_id = <0x00>;
	};

	amvdec_656in1 {
		compatible = "amlogic, amvdec_656in";
		dev_name = "amvdec_656in1";
		status = "ok";
		reg = <0x00 0xd0050000 0x00 0x7c>;
		clocks = <0x06 0x07 0x06 0x27>;
		clock-names = "fclk_div2", "cts_bt656_clk1";
		bt656_id = <0x01>;
	};

	amlvecm {
		compatible = "amlogic, vecm";
		dev_name = "aml_vecm";
		status = "okay";
		gamma_en = <0x00>;
		wb_en = <0x00>;
		cm_en = <0x00>;
	};

	amvenc_avc {
		compatible = "amlogic, amvenc_avc";
		dev_name = "amvenc_avc";
		status = "okay";
		interrupts = <0x00 0x2d 0x01>;
		interrupt-names = "mailbox_2";
	};

	hevc_enc {
		compatible = "cnm, HevcEnc";
		dev_name = "HevcEnc";
		status = "okay";
		interrupts = <0x00 0xbb 0x01>;
		interrupt-names = "wave420l_irq";
		#address-cells = <0x02>;
		#size-cells = <0x02>;
		ranges;

		io_reg_base {
			reg = <0x00 0xc8810000 0x00 0x4000>;
		};
	};

	vpu {
		compatible = "amlogic, vpu";
		dev_name = "vpu";
		status = "ok";
		clk_level = <0x07>;
	};

	bt-dev {
		compatible = "amlogic, bt-dev";
		dev_name = "bt-dev";
		status = "okay";
		gpio_reset = <0x28 0x60 0x00>;
	};

	bluetooth_exit_resume {
		compatible = "amlogic, bluetooth_exit_resume";
		dev_name = "bluetooth_exit_resume";
		status = "ok";
	};

	rtc {
		compatible = "amlogic, aml_vrtc";
		alarm_reg_addr = <0xc81000a8>;
		timer_e_addr = <0xc1109988>;
		init_date = "2015/01/01";
		status = "okay";
	};

	wifi {
		compatible = "amlogic, aml_wifi";
		dev_name = "aml_wifi";
		status = "okay";
		interrupt_pin = <0x28 0x56 0x00>;
		interrupts = <0x00 0x44 0x04>;
		irq_trigger_type = "GPIO_IRQ_LOW";
		power_on_pin = <0x28 0x55 0x00>;
		dhd_static_buf;
		pinctrl-names = "wifi_32k_pins";
		pinctrl-0 = <0x30>;
	};

	emmc {
		compatible = "amlogic, aml_sd_emmc";
		dev_name = "aml_newsd.0";
		status = "okay";
		reg = <0x00 0xd0074000 0x00 0x2000>;
		interrupts = <0x00 0xda 0x01>;
		pinctrl-names = "emmc_clk_cmd_pins", "emmc_all_pins";
		pinctrl-0 = <0x31>;
		pinctrl-1 = <0x32 0x33 0x34>;

		emmc {
			status = "disabled";
			pinname = "emmc";
			ocr_avail = <0x200080>;
			caps = "MMC_CAP_8_BIT_DATA", "MMC_CAP_MMC_HIGHSPEED", "MMC_CAP_SD_HIGHSPEED", "MMC_CAP_NONREMOVABLE", "MMC_CAP_1_8V_DDR", "MMC_CAP_HW_RESET", "MMC_CAP_ERASE", "MMC_CAP_CMD23";
			caps2 = "MMC_CAP2_HS200", "MMC_CAP2_HS400";
			f_min = <0x493e0>;
			f_max = <0x5f5e100>;
			max_req_size = <0x20000>;
			gpio_dat3 = <0x28 0x1d 0x00>;
			hw_reset = <0x28 0x23 0x00>;
			card_type = <0x01>;
		};
	};

	sd {
		compatible = "amlogic, aml_sd_emmc";
		dev_name = "aml_newsd.0";
		status = "okay";
		reg = <0x00 0xd0072000 0x00 0x2000>;
		interrupts = <0x00 0xd9 0x01 0x00 0x43 0x01 0x00 0x45 0x01>;
		pinctrl-names = "sd_clk_cmd_pins", "sd_all_pins", "sd_1bit_pins", "sd_clk_cmd_uart_pins", "sd_1bit_uart_pins", "sd_to_ao_uart_pins", "ao_to_sd_uart_pins", "ao_to_sd_jtag_pins", "sd_to_ao_jtag_pins";
		pinctrl-0 = <0x35>;
		pinctrl-1 = <0x36>;
		pinctrl-2 = <0x37>;
		pinctrl-3 = <0x38>;
		pinctrl-4 = <0x39>;
		pinctrl-5 = <0x3a>;
		pinctrl-6 = <0x3b>;
		pinctrl-7 = <0x3c>;
		pinctrl-8 = <0x3d>;

		sd {
			status = "okay";
			pinname = "sd";
			ocr_avail = <0x200080>;
			caps = "MMC_CAP_4_BIT_DATA", "MMC_CAP_MMC_HIGHSPEED", "MMC_CAP_SD_HIGHSPEED";
			f_min = <0x61a80>;
			f_max = <0x5f5e100>;
			max_req_size = <0x20000>;
			gpio_dat3 = <0x28 0x2e 0x00>;
			jtag_pin = <0x28 0x2a 0x00>;
			gpio_cd = <0x28 0x30 0x00>;
			card_in_delay = <0x190>;
			irq_in = <0x03>;
			irq_out = <0x05>;
			card_type = <0x05>;
		};
	};

	sdio {
		compatible = "amlogic, aml_sd_emmc";
		dev_name = "aml_newsd.0";
		status = "okay";
		reg = <0x00 0xd0070000 0x00 0x2000>;
		interrupts = <0x00 0xd8 0x01>;
		pinctrl-names = "sdio_clk_cmd_pins", "sdio_all_pins";
		pinctrl-0 = <0x3e>;
		pinctrl-1 = <0x3f>;

		sdio {
			status = "okay";
			pinname = "sdio";
			ocr_avail = <0x200080>;
			caps = "MMC_CAP_4_BIT_DATA", "MMC_CAP_MMC_HIGHSPEED", "MMC_CAP_SD_HIGHSPEED", "MMC_CAP_NONREMOVABLE", "MMC_CAP_UHS_SDR12", "MMC_CAP_UHS_SDR25", "MMC_CAP_UHS_SDR50", "MMC_CAP_UHS_SDR104", "MMC_PM_KEEP_POWER";
			f_min = <0x61a80>;
			f_max = <0xbebc200>;
			max_req_size = <0x20000>;
			card_type = <0x03>;
		};
	};

	nand {
		compatible = "amlogic, aml_nand";
		dev_name = "nand";
		status = "disabled";
		reg = <0x00 0xd0074800 0x00 0x200>;
		interrupts = <0x00 0x22 0x01>;
		pinctrl-names = "nand_rb_mod", "nand_norb_mod", "nand_cs_pins_only";
		pinctrl-0 = <0x40 0x41 0x42>;
		pinctrl-1 = <0x40 0x41 0x42>;
		pinctrl-2 = <0x43>;
		device_id = <0x00>;
		plat-names = "nandnormal";
		plat-num = <0x01>;
		plat-part-0 = <0x44>;

		normal {
			enable_pad = "ce0", "ce1", "ce2", "ce3";
			busy_pad = "rb0";
			linux,phandle = <0x44>;
			phandle = <0x44>;
		};
	};

	aml_nftl {
		compatible = "amlogic, nftl";
	};

	partitions {
		parts = <0x0b>;
		part-0 = <0x45>;
		part-1 = <0x46>;
		part-2 = <0x47>;
		part-3 = <0x48>;
		part-4 = <0x49>;
		part-5 = <0x4a>;
		part-6 = <0x4b>;
		part-7 = <0x4c>;
		part-8 = <0x4d>;
		part-9 = <0x4e>;
		part-10 = <0x4f>;

		logo {
			pname = "logo";
			size = <0x00 0x2000000>;
			mask = <0x01>;
			linux,phandle = <0x45>;
			phandle = <0x45>;
		};

		recovery {
			pname = "recovery";
			size = <0x00 0x2000000>;
			mask = <0x01>;
			linux,phandle = <0x46>;
			phandle = <0x46>;
		};

		rsv {
			pname = "rsv";
			size = <0x00 0x800000>;
			mask = <0x01>;
			linux,phandle = <0x47>;
			phandle = <0x47>;
		};

		tee {
			pname = "tee";
			size = <0x00 0x800000>;
			mask = <0x01>;
			linux,phandle = <0x48>;
			phandle = <0x48>;
		};

		crypt {
			pname = "crypt";
			size = <0x00 0x2000000>;
			mask = <0x01>;
			linux,phandle = <0x49>;
			phandle = <0x49>;
		};

		misc {
			pname = "misc";
			size = <0x00 0x2000000>;
			mask = <0x01>;
			linux,phandle = <0x4a>;
			phandle = <0x4a>;
		};

		instaboot {
			pname = "instaboot";
			size = <0x00 0x20000000>;
			mask = <0x01>;
			linux,phandle = <0x4b>;
			phandle = <0x4b>;
		};

		boot {
			pname = "boot";
			size = <0x00 0x2000000>;
			mask = <0x01>;
			linux,phandle = <0x4c>;
			phandle = <0x4c>;
		};

		system {
			pname = "system";
			size = <0x00 0x40000000>;
			mask = <0x01>;
			linux,phandle = <0x4d>;
			phandle = <0x4d>;
		};

		cache {
			pname = "cache";
			size = <0x00 0x20000000>;
			mask = <0x02>;
			linux,phandle = <0x4e>;
			phandle = <0x4e>;
		};

		data {
			pname = "data";
			size = <0xffffffff 0xffffffff>;
			mask = <0x04>;
			linux,phandle = <0x4f>;
			phandle = <0x4f>;
		};
	};

	unifykey {
		compatible = "amlogic, unifykey";
		status = "ok";
		unifykey-num = <0x0e>;
		unifykey-index-0 = <0x50>;
		unifykey-index-1 = <0x51>;
		unifykey-index-2 = <0x52>;
		unifykey-index-3 = <0x53>;
		unifykey-index-4 = <0x54>;
		unifykey-index-5 = <0x55>;
		unifykey-index-6 = <0x56>;
		unifykey-index-7 = <0x57>;
		unifykey-index-8 = <0x58>;
		unifykey-index-9 = <0x59>;
		unifykey-index-10 = <0x5a>;
		unifykey-index-11 = <0x5b>;
		unifykey-index-12 = <0x5c>;
		unifykey-index-13 = <0x5d>;

		key_0 {
			key-name = "usid";
			key-device = "normal";
			key-permit = "read", "write", "del";
			linux,phandle = <0x50>;
			phandle = <0x50>;
		};

		key_1 {
			key-name = "mac";
			key-device = "efuse";
			key-permit = "read", "write", "del";
			linux,phandle = <0x51>;
			phandle = <0x51>;
		};

		key_2 {
			key-name = "hdcp";
			key-device = "secure";
			key-type = "sha1";
			key-permit = "read", "write", "del";
			linux,phandle = <0x52>;
			phandle = <0x52>;
		};

		key_3 {
			key-name = "secure_boot_set";
			key-device = "efuse";
			key-permit = "write";
			linux,phandle = <0x53>;
			phandle = <0x53>;
		};

		key_4 {
			key-name = "mac_bt";
			key-device = "normal";
			key-permit = "read", "write", "del";
			key-type = "mac";
			linux,phandle = <0x54>;
			phandle = <0x54>;
		};

		key_5 {
			key-name = "mac_wifi";
			key-device = "normal";
			key-permit = "read", "write", "del";
			key-type = "mac";
			linux,phandle = <0x55>;
			phandle = <0x55>;
		};

		key_6 {
			key-name = "hdcp2_tx";
			key-device = "normal";
			key-permit = "read", "write", "del";
			linux,phandle = <0x56>;
			phandle = <0x56>;
		};

		key_7 {
			key-name = "hdcp2_rx";
			key-device = "normal";
			key-permit = "read", "write", "del";
			linux,phandle = <0x57>;
			phandle = <0x57>;
		};

		key_8 {
			key-name = "widevinekeybox";
			key-device = "secure";
			key-permit = "read", "write", "del";
			linux,phandle = <0x58>;
			phandle = <0x58>;
		};

		key_9 {
			key-name = "deviceid";
			key-device = "normal";
			key-permit = "read", "write", "del";
			linux,phandle = <0x59>;
			phandle = <0x59>;
		};

		key_10 {
			key-name = "hdcp22_fw_private";
			key-device = "secure";
			key-permit = "read", "write", "del";
			linux,phandle = <0x5a>;
			phandle = <0x5a>;
		};

		key_11 {
			key-name = "PlayReadykeybox25";
			key-device = "secure";
			key-permit = "read", "write", "del";
			linux,phandle = <0x5b>;
			phandle = <0x5b>;
		};

		key_12 {
			key-name = "prpubkeybox";
			key-device = "secure";
			key-permit = "read", "write", "del";
			linux,phandle = <0x5c>;
			phandle = <0x5c>;
		};

		key_13 {
			key-name = "prprivkeybox";
			key-device = "secure";
			key-permit = "read", "write", "del";
			linux,phandle = <0x5d>;
			phandle = <0x5d>;
		};
	};

	amhdmitx {
		compatible = "amlogic, amhdmitx";
		dev_name = "amhdmitx";
		status = "okay";
		pinctrl-names = "hdmitx_hpd", "hdmitx_ddc";
		pinctrl-0 = <0x5e>;
		pinctrl-1 = <0x5f>;
		interrupts = <0x00 0x39 0x01>;
		interrupt-names = "hdmitx_hpd";
		clocks = <0x06 0x0b 0x06 0x0c 0x06 0x0d 0x06 0x0e 0x06 0x0f 0x06 0x16>;
		clock-names = "hdmitx_clk_sys", "hdmitx_clk_encp", "hdmitx_clk_enci", "hdmitx_clk_pixel", "hdmitx_clk_phy", "hdmitx_clk_vid";
		gpio_i2c_en = <0x01>;
		#address-cells = <0x02>;
		#size-cells = <0x02>;
		ranges;
	};

	aocec {
		compatible = "amlogic, amlogic-aocec";
		device_name = "aocec";
		status = "okay";
		vendor_name = "Amlogic";
		vendor_id = <0x00>;
		product_desc = "GXBB Mbox";
		cec_osd_string = "MBox";
		port_num = <0x01>;
		arc_port_mask = <0x00>;
		interrupts = <0x00 0xc7 0x01>;
		interrupt-names = "hdmi_aocec";
		pinctrl-names = "hdmitx_aocec";
		pinctrl-0 = <0x60>;
		reg = <0x00 0xc810023c 0x00 0x04 0x00 0xc8100000 0x00 0x200>;
	};

	tvout {
		compatible = "amlogic, tvout";
		dev_name = "tvout";
		status = "okay";
	};

	i2c_gpio {
		compatible = "i2c-gpio";
		status = "okay";
		dev_name = "i2c-gpio";
		i2c-gpio,delay-us = <0x0a>;
		gpios = <0x28 0x11 0x00 0x28 0x12 0x00>;
		#address-cells = <0x02>;
		#size-cells = <0x02>;
		i2c-gpio,timeout-ms = <0x0a>;

		i2c_gpio_edid {
			compatible = "i2c-gpio-edid";
			reg = <0x50 0x00 0x00 0x00>;
		};
	};

	rtc_i2c_gpio {
		compatible = "i2c-gpio";
		status = "okay";
		dev_name = "i2c-gpio-rtc";
		pinctrl-names = "rtc_i2c_hym8563_pin";
		pinctrl-0 = <0x61>;
		i2c-gpio,delay-us = <0x02>;
		gpios = <0x28 0x43 0x00 0x28 0x44 0x00>;
		#address-cells = <0x02>;
		#size-cells = <0x02>;
		i2c-gpio,timeout-ms = <0x0a>;

		i2c_hym8563 {
			compatible = "i2c-hym8563";
			reg = <0x51 0x00 0x00 0x00>;
		};
	};

	serial@c81004c0 {
		compatible = "amlogic, meson-uart";
		reg = <0x00 0xc81004c0 0x00 0x18>;
		interrupts = <0x00 0xc1 0x01>;
		status = "okay";
		clocks = <0x06 0x02>;
		clock-names = "clk_uart";
		xtal_tick_en = <0x01>;
		fifosize = <0x40>;
		pinctrl-names = "default";
		support-sysrq = <0x00>;
	};

	serial@c11084c0 {
		compatible = "amlogic, meson-uart";
		reg = <0x00 0xc11084c0 0x00 0x18>;
		interrupts = <0x00 0x1a 0x01>;
		status = "okay";
		clocks = <0x06 0x02>;
		clock-names = "clk_uart";
		fifosize = <0x80>;
		pinctrl-names = "default";
		pinctrl-0 = <0x62>;
		resets = <0x06 0x0d>;
	};

	serial@c11084dc {
		compatible = "amlogic, meson-uart";
		reg = <0x00 0xc11084dc 0x00 0x18>;
		interrupts = <0x00 0x4b 0x01>;
		status = "disable";
		clocks = <0x06 0x02>;
		clock-names = "clk_uart";
		fifosize = <0x40>;
		pinctrl-names = "default";
		pinctrl-0 = <0x63>;
		resets = <0x06 0x30>;
	};

	serial@c1108700 {
		compatible = "amlogic, meson-uart";
		reg = <0x00 0xc1108700 0x00 0x18>;
		interrupts = <0x00 0x5d 0x01>;
		status = "disable";
		clocks = <0x06 0x02>;
		clock-names = "clk_uart";
		fifosize = <0x40>;
		pinctrl-names = "default";
		pinctrl-0 = <0x64>;
		resets = <0x06 0x4f>;
	};

	serial@c81004e0 {
		compatible = "amlogic, meson-uart";
		reg = <0x00 0xc81004e0 0x00 0x18>;
		interrupts = <0x00 0xc5 0x01>;
		status = "disable";
		clocks = <0x06 0x02>;
		clock-names = "clk_uart";
		fifosize = <0x40>;
		pinctrl-names = "default";
		pinctrl-0 = <0x65>;
	};

	canvas {
		compatible = "amlogic, meson, canvas";
		dev_name = "amlogic-canvas";
		status = "ok";
		reg = <0x00 0xc8838000 0x00 0x400>;
	};

	rdma {
		compatible = "amlogic, meson, rdma";
		dev_name = "amlogic-rdma";
		status = "ok";
		interrupts = <0x00 0x59 0x01>;
		interrupt-names = "rdma";
	};

	dwc3@c9000000 {
		compatible = "synopsys, dwc3";
		reg = <0x00 0xc9000000 0x00 0x100000>;
		interrupts = <0x00 0x1e 0x04>;
		usb-phy = <0x66 0x67>;
		cpu-type = "gxl";
		clock-src = "usb3.0";
	};

	usb2phy@d0078000 {
		compatible = "amlogic, amlogic-new-usb2";
		portnum = <0x03>;
		reg = <0x00 0xd0078000 0x00 0x80>;
		linux,phandle = <0x66>;
		phandle = <0x66>;
	};

	usb3phy@d0078080 {
		compatible = "amlogic, amlogic-new-usb3";
		portnum = <0x00>;
		reg = <0x00 0xd0078080 0x00 0x20>;
		interrupts = <0x00 0x10 0x04>;
		otg = <0x01>;
		gpio-vbus-power = "GPIOAO_5";
		gpios = <0x27 0x05 0x00>;
		linux,phandle = <0x67>;
		phandle = <0x67>;
	};

	dwc2_a {
		compatible = "amlogic,dwc2";
		device_name = "dwc2_a";
		reg = <0x00 0xc9100000 0x00 0x40000>;
		status = "okay";
		interrupts = <0x00 0x1f 0x04>;
		pl-periph-id = <0x00>;
		clock-src = "usb0";
		port-id = <0x00>;
		port-type = <0x02>;
		port-speed = <0x00>;
		port-config = <0x00>;
		port-dma = <0x00>;
		port-id-mode = <0x00>;
		usb-fifo = <0x2d8>;
		cpu-type = "gxl";
		controller-type = <0x03>;
		phy-reg = <0xd0078000>;
		phy-reg-size = <0xa0>;
		resets = <0x06 0x3a 0x06 0x48 0x06 0x36>;
		reset-names = "usb_general", "usb1", "usb1_to_ddr";
	};

	I2S {
		#sound-dai-cells = <0x00>;
		resets = <0x06 0x26 0x06 0x12 0x06 0x28 0x06 0x29 0x06 0x2a 0x06 0x2b 0x06 0x2c 0x06 0x2d 0x06 0x2f 0x06 0x8e 0x06 0x22>;
		reset-names = "top_glue", "aud_buf", "i2s_out", "amclk_measure", "aififo2", "aud_mixer", "mixer_reg", "adc", "top_level", "aoclk", "aud_in";
		clocks = <0x06 0x21 0x06 0x22>;
		clock-names = "mpll2", "mclk";
		compatible = "amlogic, aml-i2s-dai";
		linux,phandle = <0x72>;
		phandle = <0x72>;
	};

	SPDIF {
		#sound-dai-cells = <0x00>;
		compatible = "amlogic, aml-spdif-dai";
		resets = <0x06 0x27 0x06 0x90>;
		reset-names = "iec958", "iec958_amclk";
		clocks = <0x06 0x20 0x06 0x24 0x06 0x22 0x06 0x25 0x06 0x0a>;
		clock-names = "mpll1", "i958", "mclk", "spdif", "clk_81";
		linux,phandle = <0x73>;
		phandle = <0x73>;
	};

	PCM {
		#sound-dai-cells = <0x00>;
		compatible = "amlogic, aml-pcm-dai";
		pinctrl-names = "aml_audio_btpcm";
		pinctrl-0 = <0x68>;
		clocks = <0x06 0x1f 0x06 0x2a 0x06 0x2b>;
		clock-names = "mpll0", "pcm_mclk", "pcm_sclk";
		pcm_mode = <0x01>;
		linux,phandle = <0x74>;
		phandle = <0x74>;
	};

	i2s_platform {
		compatible = "amlogic, aml-i2s";
		interrupts = <0x00 0x1d 0x01>;
		linux,phandle = <0x70>;
		phandle = <0x70>;
	};

	pcm_platform {
		compatible = "amlogic, aml-pcm";
		linux,phandle = <0x71>;
		phandle = <0x71>;
	};

	spdif_codec {
		#sound-dai-cells = <0x00>;
		compatible = "amlogic, aml-spdif-codec";
		pinctrl-names = "aml_audio_spdif";
		pinctrl-0 = <0x69>;
		linux,phandle = <0x76>;
		phandle = <0x76>;
	};

	pcm_codec {
		#sound-dai-cells = <0x00>;
		compatible = "amlogic, pcm2BT-codec";
		linux,phandle = <0x77>;
		phandle = <0x77>;
	};

	dummy {
		#sound-dai-cells = <0x00>;
		compatible = "amlogic, aml_dummy_codec";
		status = "disable";
	};

	t9015 {
		#sound-dai-cells = <0x00>;
		compatible = "amlogic, aml_codec_T9015";
		reg = <0x00 0xc8832000 0x00 0x14>;
		status = "okay";
		linux,phandle = <0x75>;
		phandle = <0x75>;
	};

	aml_m8_snd {
		compatible = "aml, aml_snd_m8";
		status = "okay";
		aml-sound-card,format = "i2s";
		aml_sound_card,name = "AML-M8AUDIO";
		aml,audio-routing = "Ext Spk", "LOUTL", "Ext Spk", "LOUTR";
		mute_gpio-gpios = <0x28 0x15 0x00>;
		mute_inv;
		hp_disable;
		hp_paraments = <0x320 0x12c 0x00 0x05 0x01>;
		pinctrl-names = "aml_snd_m8";
		cpu_list = <0x6a 0x6b 0x6c>;
		codec_list = <0x6d 0x6e 0x6f>;
		plat_list = <0x70 0x70 0x71>;

		cpudai0 {
			sound-dai = <0x72>;
			linux,phandle = <0x6a>;
			phandle = <0x6a>;
		};

		cpudai1 {
			sound-dai = <0x73>;
			linux,phandle = <0x6b>;
			phandle = <0x6b>;
		};

		cpudai2 {
			sound-dai = <0x74>;
			linux,phandle = <0x6c>;
			phandle = <0x6c>;
		};

		codec0 {
			sound-dai = <0x75>;
			linux,phandle = <0x6d>;
			phandle = <0x6d>;
		};

		codec1 {
			sound-dai = <0x76>;
			linux,phandle = <0x6e>;
			phandle = <0x6e>;
		};

		codec2 {
			sound-dai = <0x77>;
			linux,phandle = <0x6f>;
			phandle = <0x6f>;
		};
	};

	gpio_keypad {
		compatible = "amlogic, gpio_keypad";
		status = "okay";
		scan_period = <0x14>;
		key_num = <0x01>;
		key_name = "power";
		key_code = <0x74>;
		key_pin = <0x27 0x02 0x00>;
		irq_keyup = <0x06>;
		irq_keydown = <0x07>;
	};

	aml-sensor@0 {
		compatible = "amlogic, aml-thermal";
		device_name = "thermal";
		#thermal-sensor-cells = <0x01>;
		linux,phandle = <0x78>;
		phandle = <0x78>;

		cooling_devices {

			cpufreq_cool_cluster0 {
				min_state = <0xf4240>;
				dyn_coeff = <0x8c>;
				cluster_id = <0x00>;
				node_name = "cluster0";
				device_type = "cpufreq";
			};

			cpufreq_cool_cluster1 {
				min_state = <0x7a120>;
				dyn_coeff = <0x8c>;
				cluster_id = <0x01>;
				node_name = "cluster1";
				device_type = "cpufreq";
			};

			cpucore_cool_cluster0 {
				min_state = <0x01>;
				dyn_coeff = <0x00>;
				cluster_id = <0x00>;
				node_name = "cpu_core_cluster0";
				device_type = "cpucore";
			};

			cpucore_cool_cluster1 {
				min_state = <0x01>;
				dyn_coeff = <0x00>;
				cluster_id = <0x01>;
				node_name = "cpu_core_cluster1";
				device_type = "cpucore";
			};

			gpufreq_cool {
				min_state = <0x190>;
				dyn_coeff = <0x1b5>;
				cluster_id = <0x00>;
				node_name = "t82x";
				device_type = "gpufreq";
			};

			gpucore_cool {
				min_state = <0x01>;
				dyn_coeff = <0x00>;
				cluster_id = <0x00>;
				node_name = "thermal_gpu_cores";
				device_type = "gpucore";
			};
		};

		cpu_core_cluster0 {
			#cooling-cells = <0x02>;
			linux,phandle = <0x7c>;
			phandle = <0x7c>;
		};

		cpu_core_cluster1 {
			#cooling-cells = <0x02>;
			linux,phandle = <0x7d>;
			phandle = <0x7d>;
		};

		thermal_gpu_cores {
			#cooling-cells = <0x02>;
			linux,phandle = <0x7f>;
			phandle = <0x7f>;
		};
	};

	thermal-zones {

		soc_thermal {
			polling-delay = <0x3e8>;
			polling-delay-passive = <0x64>;
			sustainable-power = <0x992>;
			thermal-sensors = <0x78 0x03>;

			trips {

				trip-point@0 {
					temperature = <0x11170>;
					hysteresis = <0x3e8>;
					type = "passive";
				};

				trip-point@1 {
					temperature = <0x13880>;
					hysteresis = <0x3e8>;
					type = "passive";
					linux,phandle = <0x79>;
					phandle = <0x79>;
				};

				trip-point@2 {
					temperature = <0x14c08>;
					hysteresis = <0x1388>;
					type = "hot";
				};

				trip-point@3 {
					temperature = <0x3f7a0>;
					hysteresis = <0x3e8>;
					type = "critical";
				};
			};

			cooling-maps {

				cpufreq_cooling_map0 {
					trip = <0x79>;
					cooling-device = <0x7a 0x00 0x04>;
					contribution = <0x400>;
				};

				cpufreq_cooling_map1 {
					trip = <0x79>;
					cooling-device = <0x7b 0x00 0x04>;
					contribution = <0x400>;
				};

				cpucore_cooling_map0 {
					trip = <0x79>;
					cooling-device = <0x7c 0x00 0x03>;
					contribution = <0x400>;
				};

				cpucore_cooling_map1 {
					trip = <0x79>;
					cooling-device = <0x7d 0x00 0x03>;
					contribution = <0x400>;
				};

				gpufreq_cooling_map {
					trip = <0x79>;
					cooling-device = <0x7e 0x00 0x04>;
					contribution = <0x400>;
				};

				gpucore_cooling_map {
					trip = <0x79>;
					cooling-device = <0x7f 0x00 0x02>;
					contribution = <0x400>;
				};
			};
		};
	};

	aml_vfd {
		compatible = "amlogic,aml_vfd";
		dev_name = "aml_vfd";
		stb_gpio = <0x28 0x17 0x00>;
		clk_gpio = <0x28 0x16 0x00>;
		data_gpio = <0x28 0x19 0x00>;
		status = "okay";
	};
};
